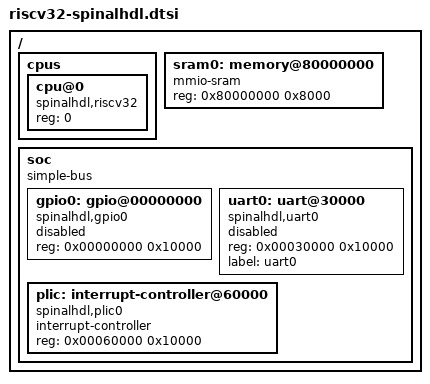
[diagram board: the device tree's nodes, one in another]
#include "skeleton.dtsi"

/ {
	cpus {
		#address-cells = <1>;
		#size-cells = <0>;

		cpu@0 {
			device_type = "cpu";
			compatible = "spinalhdl,riscv32";
			reg = <0>;
		};

	};

	sram0: memory@80000000 {
		device_type = "memory";
		compatible = "mmio-sram";
		reg = <0x80000000 0x8000>;
	};

	soc {
		#address-cells = <1>;
		#size-cells = <1>;
		compatible = "simple-bus";
		ranges;

		gpio0: gpio@00000000 {
			compatible = "spinalhdl,gpio0";
			reg = <0x00000000 0x10000>;
			status = "disabled";
		};

		uart0: uart@30000 {
			compatible = "spinalhdl,uart0";
			reg = <0x00030000 0x10000>;
			label = "uart0";

			status = "disabled";
		};

		plic: interrupt-controller@60000 {
			#interrupt-cells = <1>;
			compatible = "spinalhdl,plic0";
			interrupt-controller;
			reg = <0x00060000 0x10000>;
		};
	};
};
